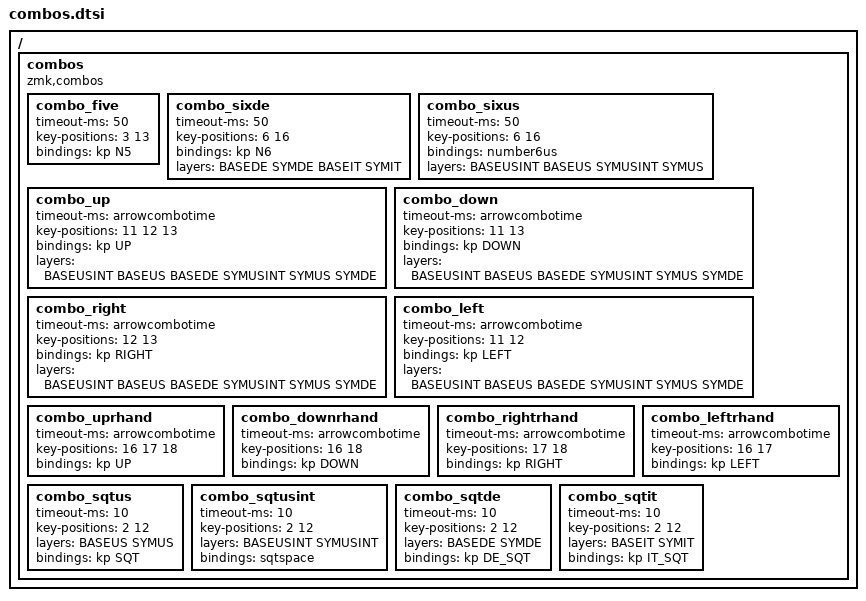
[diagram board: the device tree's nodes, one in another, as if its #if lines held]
/*                KEY POSITIONS
26 keys:
      ╭────────────────╮ ╭────────────────╮          ╭─────────────────╮ ╭────────────────╮    
  ╭───╯  0   1   2   3 │ │  4   5   6   7 ╰───╮  ╭───╯ LT3 LT2 LT1 LT0 │ │ RT0 RT1 RT2 RT3╰────╮
  │  8   9  10  11  12 │ │ 13  14  15  16  17 │  │ LM4 LM3 LM2 LM1 LM0 │ │ RM0 RM1 RM2 RM3 RM4 │
  ╰───╮ 18  19  20     │ │     21  22  23 ╭───╯  ╰───╮ LB3 LB2 LB1     │ │     RB1 RB2 RB3 ╭───╯
      ╰───────────╮ 24 │ │ 25 ╭───────────╯          ╰───────────╮ LH0 │ │ RH0 ╭───────────╯
                  ╰────╯ ╰────╯                                  ╰─────╯ ╰─────╯
30 keys:
  ╭────────────────────╮ ╭────────────────────╮  ╭─────────────────────╮ ╭─────────────────────╮
  │  0   1   2   3   4 │ │  5   6   7   8   9 │  │ LT4 LT3 LT2 LT1 LT0 │ │ RT0 RT1 RT2 RT3 RT4 │
  │ 10  11  12  13  14 │ │ 15  16  17  18  19 │  │ LM4 LM3 LM2 LM1 LM0 │ │ RM0 RM1 RM2 RM3 RM4 │
  ╰───╮ 20  21  22     │ │     23  24  25 ╭───╯  ╰───╮ LB3 LB2 LB1     │ │     RB1 RB2 RB3 ╭───╯
      ╰───────╮ 26  27 │ │ 28  29 ╭───────╯          ╰───────╮ LH1 LH0 │ │ RH0 RH1 ╭───────╯
              ╰────────╯ ╰────────╯                          ╰─────────╯ ╰─────────╯
34 keys:
  ╭────────────────────╮ ╭────────────────────╮  ╭─────────────────────╮ ╭─────────────────────╮
  │  0   1   2   3   4 │ │  5   6   7   8   9 │  │ LT4 LT3 LT2 LT1 LT0 │ │ RT0 RT1 RT2 RT3 RT4 │
  │ 10  11  12  13  14 │ │ 15  16  17  18  19 │  │ LM4 LM3 LM2 LM1 LM0 │ │ RM0 RM1 RM2 RM3 RM4 │
  │ 20  21  22  23  24 │ │ 25  26  27  28  29 │  │ LB4 LB3 LB2 LB1 LB0 │ │ RB0 RB1 RB2 RB3 RB4 │
  ╰───────────╮ 30  31 │ │ 32  33 ╭───────────╯  ╰───────────╮ LH1 LH0 │ │ RH0 RH1 ╭───────────╯
              ╰────────╯ ╰────────╯                          ╰─────────╯ ╰─────────╯
*/

#define COMBO(NAME, BINDINGS, KEYPOS, LAYERS, TIMEOUT, RPI, ...) \
    combo_##NAME {                                               \
        timeout-ms = <TIMEOUT>;                                  \
        bindings = <BINDINGS>;                                   \
        key-positions = <KEYPOS>;                                \
        layers = <LAYERS>;                                       \
        require-prior-idle-ms = <RPI>;                           \
        __VA_ARGS__                                              \
    };

#define COMBO_TERM_FAST 30
#define COMBO_TERM_MID  45
#define COMBO_TERM_SLOW 65

/ {
    combos {
        compatible = "zmk,combos";

#if defined(KEYS_34)
            combo_five {
            timeout-ms = <50>;
            key-positions = <3 13>;
            bindings = <&kp N5>;
        };
            combo_sixde {
            timeout-ms = <50>;
            key-positions = <6 16>;
            bindings = <&kp N6>;
            layers = <BASEDE SYMDE BASEIT SYMIT>;
        };
            combo_sixus {
            timeout-ms = <50>;
            key-positions = <6 16>;
            bindings = <&number6us>; // LS(6)->&
            layers = <BASEUSINT BASEUS SYMUSINT SYMUS>;
        };
            combo_up {
            timeout-ms = <arrowcombotime>;
            key-positions = <11 12 13>;
            bindings = <&kp UP>;
            layers = <BASEUSINT BASEUS BASEDE SYMUSINT SYMUS SYMDE>;
        };
            combo_down {
            timeout-ms = <arrowcombotime>;
            key-positions = <11 13>;
            bindings = <&kp DOWN>;
            layers = <BASEUSINT BASEUS BASEDE SYMUSINT SYMUS SYMDE>;
        };
            combo_right {
            timeout-ms = <arrowcombotime>;
            key-positions = <12 13>;
            bindings = <&kp RIGHT>;
            layers = <BASEUSINT BASEUS BASEDE SYMUSINT SYMUS SYMDE>;
        };
            combo_left {
            timeout-ms = <arrowcombotime>;
            key-positions = <11 12>;
            bindings = <&kp LEFT>;
            layers = <BASEUSINT BASEUS BASEDE SYMUSINT SYMUS SYMDE>;
        };

        combo_uprhand {
            timeout-ms = <arrowcombotime>;
            key-positions = <16 17 18>;
            bindings = <&kp UP>;
        };
            combo_downrhand {
            timeout-ms = <arrowcombotime>;
            key-positions = <16 18>;
            bindings = <&kp DOWN>;
        };
            combo_rightrhand {
            timeout-ms = <arrowcombotime>;
            key-positions = <17 18>;
            bindings = <&kp RIGHT>;
        };
            combo_leftrhand {
            timeout-ms = <arrowcombotime>;
            key-positions = <16 17>;
            bindings = <&kp LEFT>;
        };
            combo_sqtus {
            timeout-ms = <10>;
            key-positions = <2 12>;
            layers = <BASEUS SYMUS>;
            bindings = <&kp SQT>;
        };
            combo_sqtusint {
            timeout-ms = <10>;
            key-positions = <2 12>;
            layers  = <BASEUSINT SYMUSINT>;
            bindings = <&sqtspace>;
        };
            combo_sqtde {
            timeout-ms = <10>;
            key-positions = <2 12>;
            layers = <BASEDE SYMDE>;
            bindings = <&kp DE_SQT>;
        };
            combo_sqtit {
            timeout-ms = <10>;
            key-positions = <2 12>;
            layers = <BASEIT SYMIT>;
            bindings = <&kp IT_SQT>;
        };
#else
        COMBO(prcnt,     &kp DE_PRCNT,   LT1 LT0,     DEF,     COMBO_TERM_MID,  200)
        COMBO(tilde,     &kp DE_TILDE,   LB1 LM0,     DEF,     COMBO_TERM_MID,  200)

        COMBO(caret,     &kp DE_CARET,   RT0 RT1,     DEF,     COMBO_TERM_MID,  200)
        COMBO(qt_grv,    &qt_grv,        RB1 RM0,     DEF,     COMBO_TERM_MID,  200)
#endif

      
    };
};
